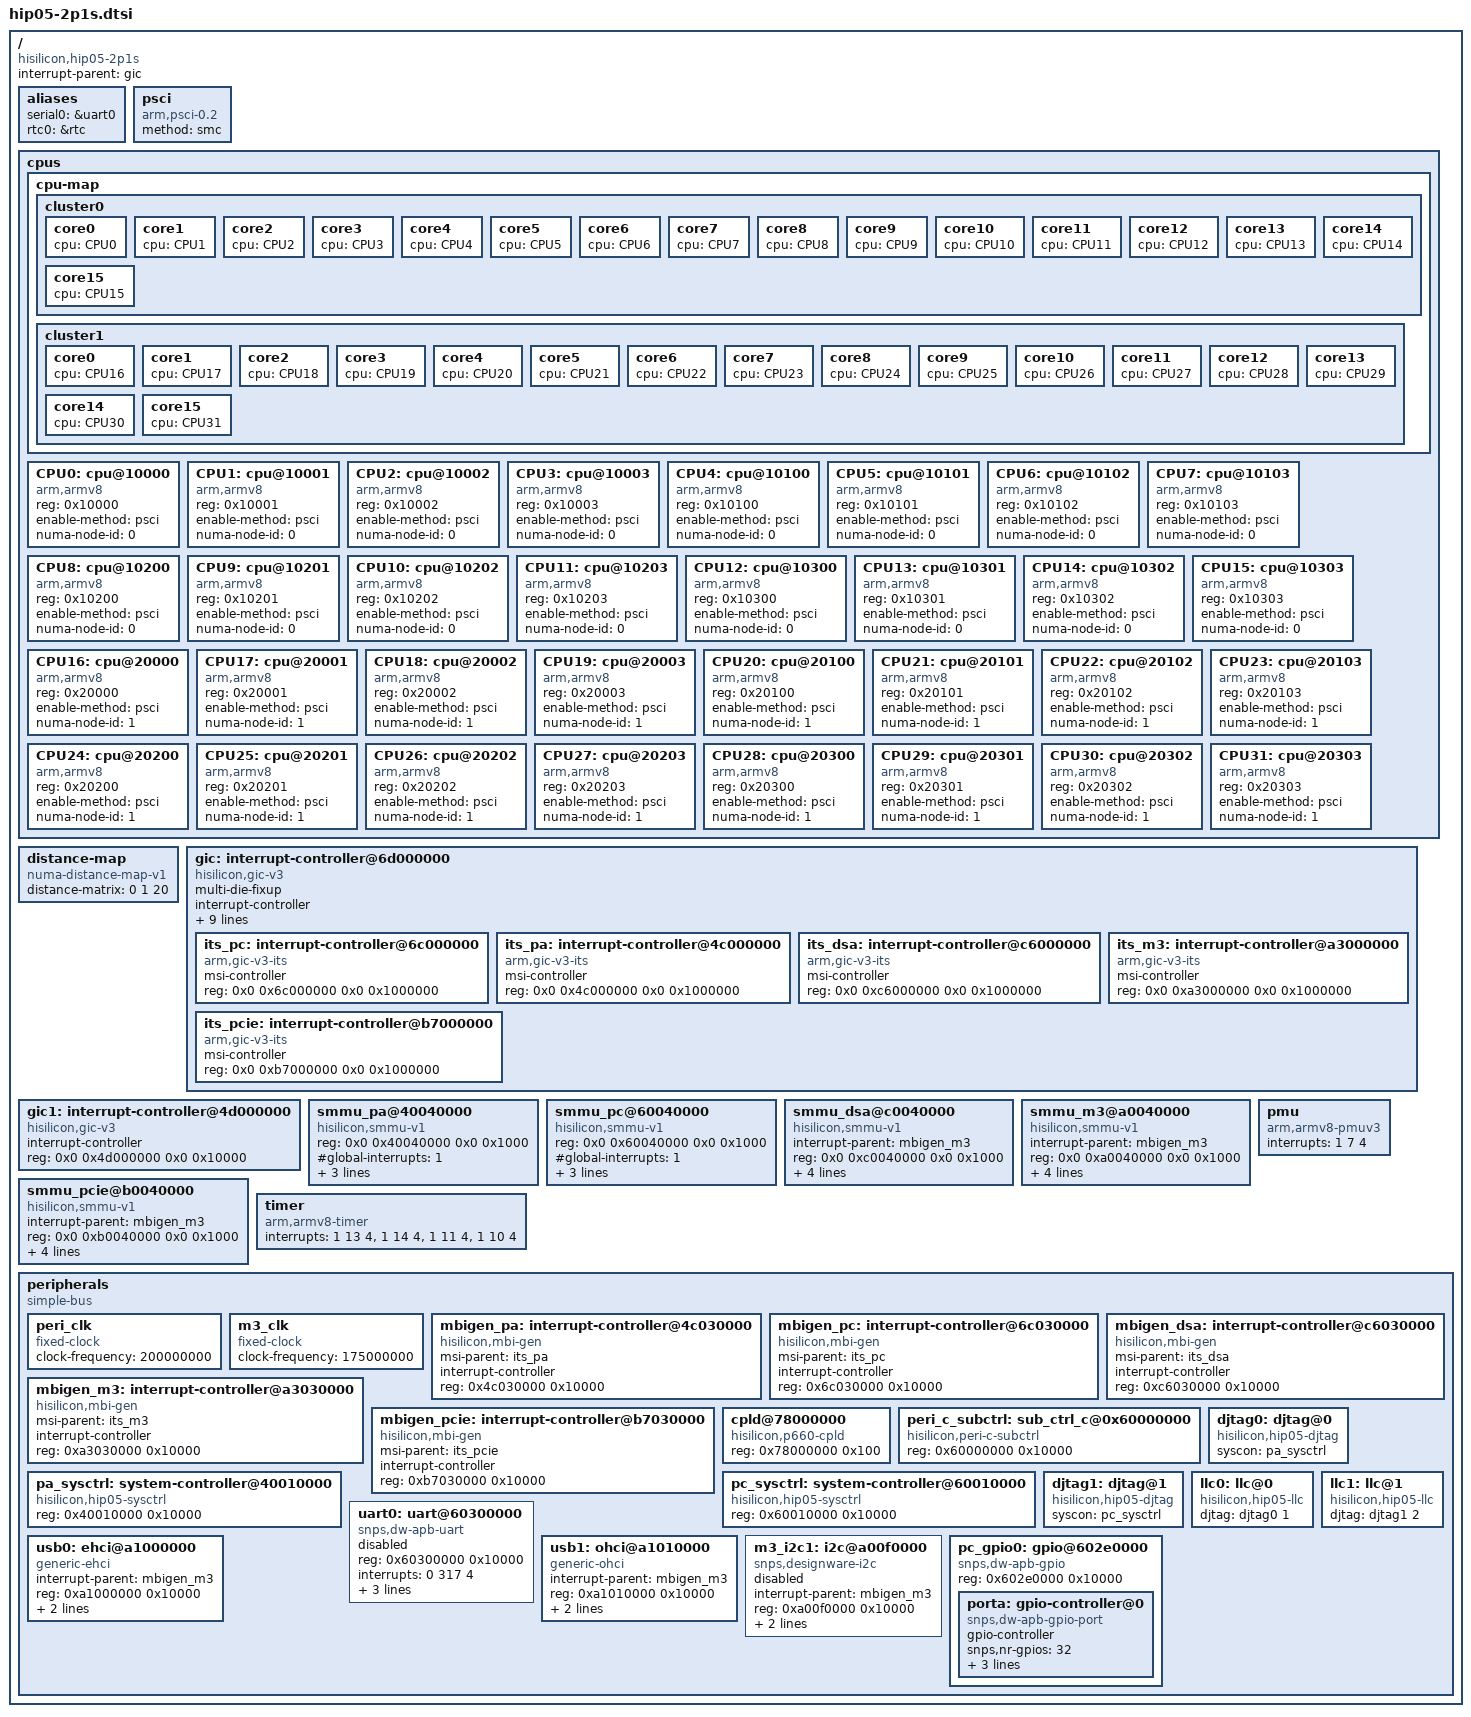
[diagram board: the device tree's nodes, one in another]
/**
 * dts file for Hisilicon PhosphorV660 Hip05 Soc
 *
 * Copyright (C) 2014,2015 Hisilicon Ltd.
 *
 * This program is free software; you can redistribute it and/or modify
 * it under the terms of the GNU General Public License version 2 as
 * publishhed by the Free Software Foundation.
 *
 */

/ {
	compatible = "hisilicon,hip05-2p1s", "hisilicon,hisi-pv660";
	interrupt-parent = <&gic>;
	#address-cells = <2>;
	#size-cells = <2>;

	aliases {
		serial0 = &uart0;
		rtc0	= &rtc;
	};

	psci {
		compatible = "arm,psci-0.2";
		method = "smc";
	};

	cpus {
		#address-cells = <1>;
		#size-cells = <0>;

		cpu-map {
			cluster0 {
				core0 {
					cpu = <&CPU0>;
				};

				core1 {
					cpu = <&CPU1>;
				};

				core2 {
					cpu = <&CPU2>;
				};

				core3 {
					cpu = <&CPU3>;
				};

				core4 {
					cpu = <&CPU4>;
				};

				core5 {
					cpu = <&CPU5>;
				};

				core6 {
					cpu = <&CPU6>;
				};

				core7 {
					cpu = <&CPU7>;
				};

				core8 {
					cpu = <&CPU8>;
				};

				core9 {
					cpu = <&CPU9>;
				};

				core10 {
					cpu = <&CPU10>;
				};

				core11 {
					cpu = <&CPU11>;
				};

				core12 {
					cpu = <&CPU12>;
				};

				core13 {
					cpu = <&CPU13>;
				};

				core14 {
					cpu = <&CPU14>;
				};

				core15 {
					cpu = <&CPU15>;
				};
			};

			cluster1 {
				core0 {
					cpu = <&CPU16>;
				};

				core1 {
					cpu = <&CPU17>;
				};

				core2 {
					cpu = <&CPU18>;
				};

				core3 {
					cpu = <&CPU19>;
				};

				core4 {
					cpu = <&CPU20>;
				};

				core5 {
					cpu = <&CPU21>;
				};

				core6 {
					cpu = <&CPU22>;
				};

				core7 {
					cpu = <&CPU23>;
				};

				core8 {
					cpu = <&CPU24>;
				};

				core9 {
					cpu = <&CPU25>;
				};

				core10 {
					cpu = <&CPU26>;
				};

				core11 {
					cpu = <&CPU27>;
				};

				core12 {
					cpu = <&CPU28>;
				};

				core13 {
					cpu = <&CPU29>;
				};

				core14 {
					cpu = <&CPU30>;
				};

				core15 {
					cpu = <&CPU31>;
				};
			};
		};

		CPU0: cpu@10000 {
			device_type = "cpu";
			compatible = "arm,armv8";
			reg = <0x10000>;
			enable-method = "psci";
			numa-node-id = <0>;
		};

		CPU1: cpu@10001 {
			device_type = "cpu";
			compatible = "arm,armv8";
			reg = <0x10001>;
			enable-method = "psci";
			numa-node-id = <0>;
		};

		CPU2: cpu@10002 {
			device_type = "cpu";
			compatible = "arm,armv8";
			reg = <0x10002>;
			enable-method = "psci";
			numa-node-id = <0>;
		};

		CPU3: cpu@10003 {
			device_type = "cpu";
			compatible = "arm,armv8";
			reg = <0x10003>;
			enable-method = "psci";
			numa-node-id = <0>;
		};

		CPU4: cpu@10100 {
			device_type = "cpu";
			compatible = "arm,armv8";
			reg = <0x10100>;
			enable-method = "psci";
			numa-node-id = <0>;
		};

		CPU5: cpu@10101 {
			device_type = "cpu";
			compatible = "arm,armv8";
			reg = <0x10101>;
			enable-method = "psci";
			numa-node-id = <0>;
		};

		CPU6: cpu@10102 {
			device_type = "cpu";
			compatible = "arm,armv8";
			reg = <0x10102>;
			enable-method = "psci";
			numa-node-id = <0>;
		};

		CPU7: cpu@10103 {
			device_type = "cpu";
			compatible = "arm,armv8";
			reg = <0x10103>;
			enable-method = "psci";
			numa-node-id = <0>;
		};

		CPU8: cpu@10200 {
			device_type = "cpu";
			compatible = "arm,armv8";
			reg = <0x10200>;
			enable-method = "psci";
			numa-node-id = <0>;
		};

		CPU9: cpu@10201 {
			device_type = "cpu";
			compatible = "arm,armv8";
			reg = <0x10201>;
			enable-method = "psci";
			numa-node-id = <0>;
		};

		CPU10: cpu@10202 {
			device_type = "cpu";
			compatible = "arm,armv8";
			reg = <0x10202>;
			enable-method = "psci";
			numa-node-id = <0>;
		};

		CPU11: cpu@10203 {
			device_type = "cpu";
			compatible = "arm,armv8";
			reg = <0x10203>;
			enable-method = "psci";
			numa-node-id = <0>;
		};

		CPU12: cpu@10300 {
			device_type = "cpu";
			compatible = "arm,armv8";
			reg = <0x10300>;
			enable-method = "psci";
			numa-node-id = <0>;
		};

		CPU13: cpu@10301 {
			device_type = "cpu";
			compatible = "arm,armv8";
			reg = <0x10301>;
			enable-method = "psci";
			numa-node-id = <0>;
		};

		CPU14: cpu@10302 {
			device_type = "cpu";
			compatible = "arm,armv8";
			reg = <0x10302>;
			enable-method = "psci";
			numa-node-id = <0>;
		};

		CPU15: cpu@10303 {
			device_type = "cpu";
			compatible = "arm,armv8";
			reg = <0x10303>;
			enable-method = "psci";
			numa-node-id = <0>;
		};

		CPU16: cpu@20000 {
			device_type = "cpu";
			compatible = "arm,armv8";
			reg = <0x20000>;
			enable-method = "psci";
			numa-node-id = <1>;
		};

		CPU17: cpu@20001 {
			device_type = "cpu";
			compatible = "arm,armv8";
			reg = <0x20001>;
			enable-method = "psci";
			numa-node-id = <1>;
		};

		CPU18: cpu@20002 {
			device_type = "cpu";
			compatible = "arm,armv8";
			reg = <0x20002>;
			enable-method = "psci";
			numa-node-id = <1>;
		};

		CPU19: cpu@20003 {
			device_type = "cpu";
			compatible = "arm,armv8";
			reg = <0x20003>;
			enable-method = "psci";
			numa-node-id = <1>;
		};

		CPU20: cpu@20100 {
			device_type = "cpu";
			compatible = "arm,armv8";
			reg = <0x20100>;
			enable-method = "psci";
			numa-node-id = <1>;
		};

		CPU21: cpu@20101 {
			device_type = "cpu";
			compatible = "arm,armv8";
			reg = <0x20101>;
			enable-method = "psci";
			numa-node-id = <1>;
		};

		CPU22: cpu@20102 {
			device_type = "cpu";
			compatible = "arm,armv8";
			reg = <0x20102>;
			enable-method = "psci";
			numa-node-id = <1>;
		};

		CPU23: cpu@20103 {
			device_type = "cpu";
			compatible = "arm,armv8";
			reg = <0x20103>;
			enable-method = "psci";
			numa-node-id = <1>;
		};

		CPU24: cpu@20200 {
			device_type = "cpu";
			compatible = "arm,armv8";
			reg = <0x20200>;
			enable-method = "psci";
			numa-node-id = <1>;
		};

		CPU25: cpu@20201 {
			device_type = "cpu";
			compatible = "arm,armv8";
			reg = <0x20201>;
			enable-method = "psci";
			numa-node-id = <1>;
		};

		CPU26: cpu@20202 {
			device_type = "cpu";
			compatible = "arm,armv8";
			reg = <0x20202>;
			enable-method = "psci";
			numa-node-id = <1>;
		};

		CPU27: cpu@20203 {
			device_type = "cpu";
			compatible = "arm,armv8";
			reg = <0x20203>;
			enable-method = "psci";
			numa-node-id = <1>;
		};

		CPU28: cpu@20300 {
			device_type = "cpu";
			compatible = "arm,armv8";
			reg = <0x20300>;
			enable-method = "psci";
			numa-node-id = <1>;
		};

		CPU29: cpu@20301 {
			device_type = "cpu";
			compatible = "arm,armv8";
			reg = <0x20301>;
			enable-method = "psci";
			numa-node-id = <1>;
		};

		CPU30: cpu@20302 {
			device_type = "cpu";
			compatible = "arm,armv8";
			reg = <0x20302>;
			enable-method = "psci";
			numa-node-id = <1>;
		};

		CPU31: cpu@20303 {
			device_type = "cpu";
			compatible = "arm,armv8";
			reg = <0x20303>;
			enable-method = "psci";
			numa-node-id = <1>;
		};
	};

	distance-map {
		compatible = "numa-distance-map-v1";
		distance-matrix = <0 1 20>;
	};

	gic: interrupt-controller@6d000000 {
		compatible = "hisilicon,gic-v3";
                #interrupt-cells = <3>;
                #address-cells = <2>;
                #size-cells = <2>;
                ranges;
		multi-die-fixup;
                interrupt-controller;
                #redistributor-regions = <2>;
                redistributor-stride = <0x0 0x30000>;
		reg = <0x0 0x6d000000 0x0 0x10000>,	/* GICD C*/
		      <0x0 0x6d100000 0x0 0x300000>,	/* GICR C*/
		      <0x0 0x4d100000 0x0 0x300000>,	/* GICR A*/
		      <0x0 0xfe000000 0x0 0x10000>,	/* GICC */
		      <0x0 0xfe010000 0x0 0x10000>,     /* GICH */
		      <0x0 0xfe020000 0x0 0x10000>;     /* GICV */
		interrupts = <1 9 0xff04>;

		its_pc: interrupt-controller@6c000000 {
			compatible = "arm,gic-v3-its";
			msi-controller;
			reg = <0x0 0x6c000000 0x0 0x1000000>;
		};

		its_pa: interrupt-controller@4c000000 {
			compatible = "arm,gic-v3-its";
			msi-controller;
			reg = <0x0 0x4c000000 0x0 0x1000000>;
		};

		its_dsa: interrupt-controller@c6000000 {
			compatible = "arm,gic-v3-its";
			msi-controller;
			reg = <0x0 0xc6000000 0x0 0x1000000>;
		};

		its_m3: interrupt-controller@a3000000 {
			compatible = "arm,gic-v3-its";
			msi-controller;
			reg = <0x0 0xa3000000 0x0 0x1000000>;
		};

		its_pcie: interrupt-controller@b7000000 {
			compatible = "arm,gic-v3-its";
			msi-controller;
			reg = <0x0 0xb7000000 0x0 0x1000000>;
		};
	};

	gic1: interrupt-controller@4d000000 {
		compatible = "hisilicon,gic-v3";
		#interrupt-cells = <3>;
		#address-cells = <2>;
		#size-cells = <2>;
		interrupt-controller;
		reg = <0x0 0x4d000000 0x0 0x10000>;
	};

	smmu_pa@40040000 {
		compatible = "hisilicon,smmu-v1";
		reg = <0x0 0x40040000 0x0 0x1000>;
		#global-interrupts = <1>;
		interrupts = <0 188 4>,
			     <0 188 4>;
		smmu-cb-memtype = <0 1>;
		smmu-bypass-vmid = <0xff>;
	};

	smmu_pc@60040000 {
		compatible = "hisilicon,smmu-v1";
		reg = <0x0 0x60040000 0x0 0x1000>;
		#global-interrupts = <1>;
		interrupts = <0 316 4>,
			     <0 316 4>;
		smmu-cb-memtype = <0 1>;
		smmu-bypass-vmid = <0xff>;
	};

	smmu_dsa@c0040000 {
		compatible = "hisilicon,smmu-v1";
		interrupt-parent = <&mbigen_m3>;
		reg = <0x0 0xc0040000 0x0 0x1000>;
		#global-interrupts = <1>;
		interrupts = <69 4>,
			     <69 4>;
		smmu-cb-memtype = <0 1>;
		smmu-bypass-vmid = <0xff>;
	};

	smmu_m3@a0040000 {
		compatible = "hisilicon,smmu-v1";
		interrupt-parent = <&mbigen_m3>;
		reg = <0x0 0xa0040000 0x0 0x1000>;
		#global-interrupts = <1>;
		interrupts = <65 1>,
			     <65 1>;
		smmu-cb-memtype = <0 1>;
		smmu-bypass-vmid = <0xff>;
	};

	smmu_pcie@b0040000 {
		compatible = "hisilicon,smmu-v1";
		interrupt-parent = <&mbigen_m3>;
		reg = <0x0 0xb0040000 0x0 0x1000>;
		#global-interrupts = <1>;
		interrupts = <71 1>,
			     <71 1>;
		smmu-cb-memtype = <0 1>, <1 3>;
		smmu-bypass-vmid = <0xff>;
	};

	timer {
		compatible = "arm,armv8-timer";
		interrupts = <1 13 4>,
			     <1 14 4>,
			     <1 11 4>,
			     <1 10 4>;
	};

	pmu {
		compatible = "arm,armv8-pmuv3";
		interrupts = <1 7 4>;
	};

	peripherals {
		compatible = "simple-bus";
		#address-cells = <1>;
		#size-cells = <1>;
		ranges = <0x0 0x00000000 0x0 0xffffffff>;

		peri_clk: peri_clk {
			compatible = "fixed-clock";
			#clock-cells = <0>;
			clock-frequency = <200000000>;
		};

		m3_clk: m3_clk {
			compatible = "fixed-clock";
			#clock-cells = <0>;
			clock-frequency = <175000000>;
		};

		mbigen_pa: interrupt-controller@4c030000 {
			compatible = "hisilicon,mbi-gen";
			msi-parent = <&its_pa>;
			interrupt-controller;
			#interrupt-cells = <2>;
			reg = <0x4c030000 0x10000>;
		};

		mbigen_pc: interrupt-controller@6c030000 {
			compatible = "hisilicon,mbi-gen";
			msi-parent = <&its_pc>;
			interrupt-controller;
			#interrupt-cells = <2>;
			reg = <0x6c030000 0x10000>;
		};

		mbigen_dsa: interrupt-controller@c6030000 {
			compatible = "hisilicon,mbi-gen";
			msi-parent = <&its_dsa>;
			interrupt-controller;
			#interrupt-cells = <2>;
			reg = <0xc6030000 0x10000>;
		};

		mbigen_m3: interrupt-controller@a3030000 {
			compatible = "hisilicon,mbi-gen";
			msi-parent = <&its_m3>;
			interrupt-controller;
			#interrupt-cells = <2>;
			reg = <0xa3030000 0x10000>;
		};

		mbigen_pcie: interrupt-controller@b7030000 {
			compatible = "hisilicon,mbi-gen";
			msi-parent = <&its_pcie>;
			interrupt-controller;
			#interrupt-cells = <2>;
			reg = <0xb7030000 0x10000>;
		};

		cpld@78000000 {
			compatible = "hisilicon,p660-cpld";
			reg = <0x78000000 0x100>;
		};

		peri_c_subctrl: sub_ctrl_c@0x60000000 {
			compatible = "hisilicon,peri-c-subctrl", "syscon";
			reg = <0x60000000 0x10000>;
		};

		pa_sysctrl: system-controller@40010000 {
			compatible = "hisilicon,hip05-sysctrl", "syscon";
			reg = <0x40010000 0x10000>;
		};

		pc_sysctrl: system-controller@60010000 {
			compatible = "hisilicon,hip05-sysctrl", "syscon";
			reg = <0x60010000 0x10000>;
		};

		djtag0: djtag@0 {
			compatible = "hisilicon,hip05-djtag";
			syscon = <&pa_sysctrl>;
		};

		djtag1: djtag@1 {
			compatible = "hisilicon,hip05-djtag";
			syscon = <&pc_sysctrl>;
		};

		llc0: llc@0 {
			compatible = "hisilicon,hip05-llc";
			djtag = <&djtag0 1>;
		};

		llc1: llc@1 {
			compatible = "hisilicon,hip05-llc";
			djtag = <&djtag1 2>;
		};

		uart0: uart@60300000 {
			compatible = "snps,dw-apb-uart";
			reg = <0x60300000 0x10000>;
			interrupts = <0 317 4>;
			clocks = <&peri_clk>;
			clock-names = "apb_pclk";
			reg-shift = <2>;
			reg-io-width = <4>;
			status = "disabled";
		};

		usb0: ehci@a1000000 {
			compatible = "generic-ehci";
			interrupt-parent = <&mbigen_m3>;
			reg = <0xa1000000 0x10000>;
			interrupts = <20 4>;
			dma-coherent;
		};

		usb1: ohci@a1010000 {
			compatible = "generic-ohci";
			interrupt-parent = <&mbigen_m3>;
			reg = <0xa1010000 0x10000>;
			interrupts = <19 4>;
			dma-coherent;
		};

		m3_i2c1: i2c@a00f0000 {
			#address-cells = <1>;
			#size-cells = <0>;
			compatible = "snps,designware-i2c";
			interrupt-parent = <&mbigen_m3>;
			reg = <0xa00f0000 0x10000>;
			interrupts = <9 4>;
			clocks = <&m3_clk>;
			status = "disabled";
		};

		pc_gpio0: gpio@602e0000 {
			#address-cells = <1>;
			#size-cells = <0>;
			compatible = "snps,dw-apb-gpio";
			reg = <0x602e0000 0x10000>;

			porta: gpio-controller@0 {
				compatible = "snps,dw-apb-gpio-port";
				gpio-controller;
				#gpio-cells = <2>;
				snps,nr-gpios = <32>;
				reg = <0>;
				interrupt-controller;
				#interrupt-cells = <2>;
				interrupts = <0 312 4>;
			};
		};
	};

};
